# ATSAME54N20A register map
Vendor: Microchip Technology; Series: SAME54; File version: 0
CPU: CM4 r0p1, selectable endian, MPU, FPU, 3 interrupt priority bits
Registers are 32-bit, read-write, reset 0x0 unless marked. A register's access mark holds for its fields unless they carry their own. Offsets are from the block's base; [hi:lo] are bit positions; {n}, {i} and the like mark numbered series; 'fields as' and 'values as' point back to an identical list.

## MCLK — Main Clock
Base 0x40000800; register names take the prefix MCLK_
0x01 INTENCLR 8-bit — Interrupt Enable Clear
  [0] CKRDY — Clock Ready Interrupt Enable
0x02 INTENSET 8-bit — Interrupt Enable Set
  [0] CKRDY — Clock Ready Interrupt Enable
0x03 INTFLAG 8-bit reset 0x1 — Interrupt Flag Status and Clear
  [0] CKRDY — Clock Ready
0x04 HSDIV 8-bit ro reset 0x1 — HS Clock Division
  [7:0] DIV — CPU Clock Division Factor
    1=Divide by 1
0x05 CPUDIV 8-bit reset 0x1 — CPU Clock Division
  [7:0] DIV — Low-Power Clock Division Factor
    1=Divide by 1; 2=Divide by 2; 4=Divide by 4; 8=Divide by 8; 16=Divide by 16; 32=Divide by 32; 64=Divide by 64; 128=Divide by 128
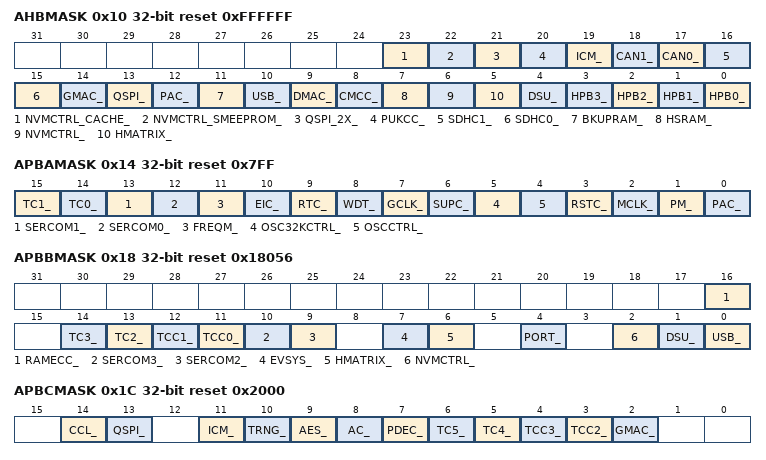
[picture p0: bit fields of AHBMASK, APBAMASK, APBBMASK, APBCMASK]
0x10 AHBMASK reset 0xFFFFFF
  [23] NVMCTRL_CACHE_ — NVMCTRL_CACHE AHB Clock Mask
  [22] NVMCTRL_SMEEPROM_ — NVMCTRL_SMEEPROM AHB Clock Mask
  [21] QSPI_2X_ — QSPI_2X AHB Clock Mask
  [20] PUKCC_ — PUKCC AHB Clock Mask
  [19] ICM_ — ICM AHB Clock Mask
  [18] CAN1_ — CAN1 AHB Clock Mask
  [17] CAN0_ — CAN0 AHB Clock Mask
  [16] SDHC1_ — SDHC1 AHB Clock Mask
  [15] SDHC0_ — SDHC0 AHB Clock Mask
  [14] GMAC_ — GMAC AHB Clock Mask
  [13] QSPI_ — QSPI AHB Clock Mask
  [12] PAC_ — PAC AHB Clock Mask
  [11] BKUPRAM_ — BKUPRAM AHB Clock Mask
  [10] USB_ — USB AHB Clock Mask
  [9] DMAC_ — DMAC AHB Clock Mask
  [8] CMCC_ — CMCC AHB Clock Mask
  [7] HSRAM_ — HSRAM AHB Clock Mask
  [6] NVMCTRL_ — NVMCTRL AHB Clock Mask
  [5] HMATRIX_ — HMATRIX AHB Clock Mask
  [4] DSU_ — DSU AHB Clock Mask
  [n] HPB{n}_ (n=0..3) — HPB{n} AHB Clock Mask
0x14 APBAMASK reset 0x7FF
  [15] TC1_ — TC1 APB Clock Enable
  [14] TC0_ — TC0 APB Clock Enable
  [13] SERCOM1_ — SERCOM1 APB Clock Enable
  [12] SERCOM0_ — SERCOM0 APB Clock Enable
  [11] FREQM_ — FREQM APB Clock Enable
  [10] EIC_ — EIC APB Clock Enable
  [9] RTC_ — RTC APB Clock Enable
  [8] WDT_ — WDT APB Clock Enable
  [7] GCLK_ — GCLK APB Clock Enable
  [6] SUPC_ — SUPC APB Clock Enable
  [5] OSC32KCTRL_ — OSC32KCTRL APB Clock Enable
  [4] OSCCTRL_ — OSCCTRL APB Clock Enable
  [3] RSTC_ — RSTC APB Clock Enable
  [2] MCLK_ — MCLK APB Clock Enable
  [1] PM_ — PM APB Clock Enable
  [0] PAC_ — PAC APB Clock Enable
0x18 APBBMASK reset 0x18056
  [16] RAMECC_ — RAMECC APB Clock Enable
  [14] TC3_ — TC3 APB Clock Enable
  [13] TC2_ — TC2 APB Clock Enable
  [12] TCC1_ — TCC1 APB Clock Enable
  [11] TCC0_ — TCC0 APB Clock Enable
  [10] SERCOM3_ — SERCOM3 APB Clock Enable
  [9] SERCOM2_ — SERCOM2 APB Clock Enable
  [7] EVSYS_ — EVSYS APB Clock Enable
  [6] HMATRIX_ — HMATRIX APB Clock Enable
  [4] PORT_ — PORT APB Clock Enable
  [2] NVMCTRL_ — NVMCTRL APB Clock Enable
  [1] DSU_ — DSU APB Clock Enable
  [0] USB_ — USB APB Clock Enable
0x1C APBCMASK reset 0x2000
  [14] CCL_ — CCL APB Clock Enable
  [13] QSPI_ — QSPI APB Clock Enable
  [11] ICM_ — ICM APB Clock Enable
  [10] TRNG_ — TRNG APB Clock Enable
  [9] AES_ — AES APB Clock Enable
  [8] AC_ — AC APB Clock Enable
  [7] PDEC_ — PDEC APB Clock Enable
  [6] TC5_ — TC5 APB Clock Enable
  [5] TC4_ — TC4 APB Clock Enable
  [4] TCC3_ — TCC3 APB Clock Enable
  [3] TCC2_ — TCC2 APB Clock Enable
  [2] GMAC_ — GMAC APB Clock Enable
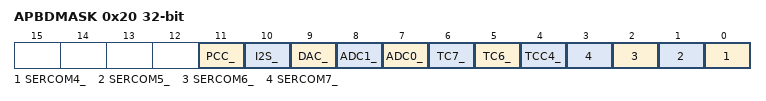
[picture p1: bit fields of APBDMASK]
0x20 APBDMASK
  [11] PCC_ — PCC APB Clock Enable
  [10] I2S_ — I2S APB Clock Enable
  [9] DAC_ — DAC APB Clock Enable
  [8] ADC1_ — ADC1 APB Clock Enable
  [7] ADC0_ — ADC0 APB Clock Enable
  [6] TC7_ — TC7 APB Clock Enable
  [5] TC6_ — TC6 APB Clock Enable
  [4] TCC4_ — TCC4 APB Clock Enable
  [n-4] SERCOM{n}_ (n=4..7) — SERCOM{n} APB Clock Enable

## OSC32KCTRL — 32kHz Oscillators Control
Base 0x40001400; register names take the prefix OSC32KCTRL_
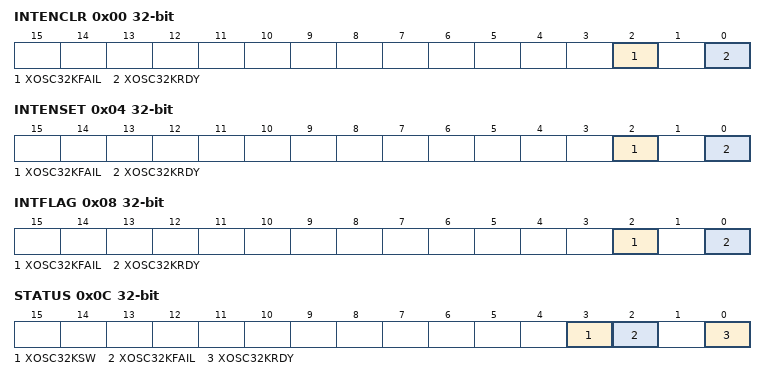
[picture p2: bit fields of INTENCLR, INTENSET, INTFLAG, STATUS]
0x00 INTENCLR — Interrupt Enable Clear
  [2] XOSC32KFAIL — XOSC32K Clock Failure Detector Interrupt Enable
  [0] XOSC32KRDY — XOSC32K Ready Interrupt Enable
0x04 INTENSET — Interrupt Enable Set
  fields as INTENCLR
0x08 INTFLAG — Interrupt Flag Status and Clear
  [2] XOSC32KFAIL — XOSC32K Clock Failure Detector
  [0] XOSC32KRDY — XOSC32K Ready
0x0C STATUS ro — Power and Clocks Status
  [3] XOSC32KSW — XOSC32K Clock switch
  [2] XOSC32KFAIL — XOSC32K Clock Failure Detector
  [0] XOSC32KRDY — XOSC32K Ready
0x10 RTCCTRL 8-bit — RTC Clock Selection
  [2:0] RTCSEL
    0=ULP1K (1.024kHz from 32kHz internal ULP oscillator); 1=ULP32K (32.768kHz from 32kHz internal ULP oscillator); 4=XOSC1K (1.024kHz from 32.768kHz internal oscillator); 5=XOSC32K (32.768kHz from 32.768kHz external crystal oscillator)
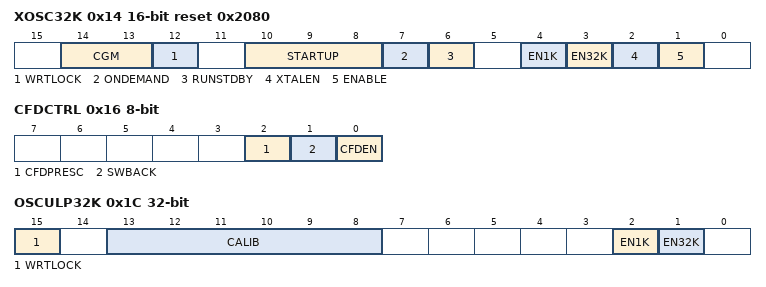
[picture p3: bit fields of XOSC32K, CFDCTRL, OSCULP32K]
0x14 XOSC32K 16-bit reset 0x2080 — 32kHz External Crystal Oscillator (XOSC32K) Control
  [14:13] CGM — Control Gain Mode
    1=XT (Standard mode); 2=HS (High Speed mode)
  [12] WRTLOCK — Write Lock
  [10:8] STARTUP — Oscillator Start-Up Time
    0=CYCLE2048 (62.6 ms); 1=CYCLE4096 (125 ms); 2=CYCLE16384 (500 ms); 3=CYCLE32768 (1000 ms); 4=CYCLE65536 (2000 ms); 5=CYCLE131072 (4000 ms); 6=CYCLE262144 (8000 ms)
  [7] ONDEMAND — On Demand Control
  [6] RUNSTDBY — Run in Standby
  [4] EN1K — 1kHz Output Enable
  [3] EN32K — 32kHz Output Enable
  [2] XTALEN — Crystal Oscillator Enable
  [1] ENABLE — Oscillator Enable
0x16 CFDCTRL 8-bit — Clock Failure Detector Control
  [2] CFDPRESC — Clock Failure Detector Prescaler
  [1] SWBACK — Clock Switch Back
  [0] CFDEN — Clock Failure Detector Enable
0x17 EVCTRL 8-bit — Event Control
  [0] CFDEO — Clock Failure Detector Event Output Enable
0x1C OSCULP32K — 32kHz Ultra Low Power Internal Oscillator (OSCULP32K) Control
  [15] WRTLOCK — Write Lock
  [13:8] CALIB — Oscillator Calibration
  [2] EN1K — Enable Out 1k
  [1] EN32K — Enable Out 32k

## Notices in the file
Copyright (c) 2017 Microchip Technology Inc.
SPDX-License-Identifier: Apache-2.0
Licensed under the Apache License, Version 2.0 (the "License");
you may not use this file except in compliance with the License.
You may obtain a copy of the License at
http://www.apache.org/licenses/LICENSE-2.0
Unless required by applicable law or agreed to in writing, software
distributed under the License is distributed on an "AS IS" BASIS,
WITHOUT WARRANTIES OR CONDITIONS OF ANY KIND, either express or implied.
See the License for the specific language governing permissions and
limitations under the License.
